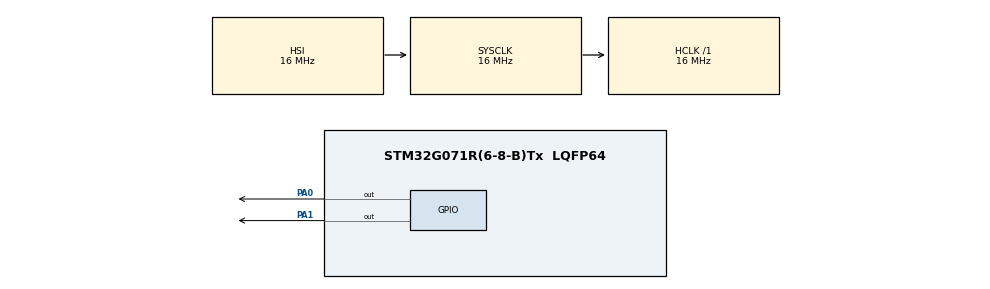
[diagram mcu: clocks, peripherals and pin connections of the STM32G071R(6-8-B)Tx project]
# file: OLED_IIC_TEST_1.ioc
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Mcu.Family=STM32G0
Mcu.Name=STM32G071R(6-8-B)Tx
Mcu.Package=LQFP64
PA0.Signal=GPIO_Output
PA1.Signal=GPIO_Output
ProjectManager.HeapSize=0x200
ProjectManager.StackSize=0x400
ProjectManager.TargetToolchain=MDK-ARM V5.27
RCC.AHBFreq_Value=16000000
RCC.CortexFreq_Value=16000000
RCC.EXTERNAL_CLOCK_VALUE=48000
RCC.HCLKFreq_Value=16000000
RCC.HSE_VALUE=8000000
RCC.HSI_VALUE=16000000
RCC.LSE_VALUE=32768
RCC.SYSCLKFreq_VALUE=16000000
RCC.VCOOutputFreq_Value=128000000
VP_SYS_VS_DBSignals.Mode=DisableDeadBatterySignals
board=custom

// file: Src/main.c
/**************************
		识别图像
		①下载图片
		②打开PS将图片像素改为128*64
		③数据水平，字节垂直
		④字节内像素数据反序
		生成矩阵
		改成二维矩阵（便于理解）
**************************/

/**************************
   GND  电源地
   VCC  接5V或3.3v电源
   D0   PA0（SCL）
   D1   PA1（SDA）
   RES  接高
   DC   接地
   CS   接地
**************************/

#include "main.h"
#define SET		1
#define RESET 0

const unsigned char biaoqinbao[][128] =
{
0X00,0X00,0X00,0X00,0X00,0X00,0X00,0X00,0X00,0X00,0X00,0X00,0X00,0X00,0X00,0X00,
0X00,0X00,0X00,0X00,0X00,0X00,0X00,0X00,0X00,0X00,0X00,0X00,0X00,0X00,0X00,0X00,
0X00,0X00,0X00,0X00,0X00,0X00,0X00,0X00,0X00,0X00,0X00,0X00,0X00,0X00,0X00,0X00,
0X00,0X00,0X00,0X00,0X00,0X00,0X00,0X00,0X00,0X00,0X00,0X00,0X00,0X00,0X00,0X00,
0X00,0X00,0X00,0X00,0X00,0X00,0X00,0X00,0X00,0X00,0X00,0X00,0X00,0X00,0X00,0X00,
0X00,0X00,0X00,0X00,0X00,0X00,0X00,0X00,0X00,0X00,0X00,0X00,0X00,0X00,0X00,0X00,
0X00,0X00,0X00,0X00,0X00,0X00,0X00,0X00,0X00,0X00,0X00,0X00,0X00,0X00,0X00,0X00,
0X00,0X00,0X00,0X00,0X00,0X00,0X00,0X00,0X00,0X00,0X00,0X00,0X00,0X00,0X00,0X00,
0X00,0X00,0X00,0X00,0X00,0X00,0X00,0X00,0X00,0X00,0X00,0X00,0X00,0X00,0X00,0X00,
0X00,0X00,0X00,0X00,0X00,0X00,0X00,0X00,0X00,0X00,0X00,0X00,0X00,0X00,0X00,0X00,
0X00,0X00,0X00,0X00,0X00,0X00,0X00,0X00,0X00,0X00,0X00,0X00,0X00,0X00,0X00,0X00,
0X00,0X00,0X00,0X00,0X00,0X00,0X00,0X80,0X80,0XC0,0XC0,0X60,0X60,0X30,0X30,0X30,
0X30,0X30,0X30,0X30,0X30,0X30,0X30,0X30,0XB0,0X30,0X20,0X60,0X60,0XC0,0XC0,0X80,
0X80,0X00,0X00,0X00,0X00,0X00,0X00,0X00,0X00,0X00,0X00,0X00,0X00,0X00,0X00,0X00,
0X00,0X00,0X00,0X00,0X00,0X00,0X00,0X00,0X00,0X00,0X00,0X00,0X00,0X00,0X00,0X00,
0X00,0X00,0X00,0X00,0X00,0X00,0X00,0X00,0X00,0X00,0X00,0X00,0X00,0X00,0X00,0X00,
0X00,0X00,0X00,0X00,0X00,0X00,0X00,0X00,0X00,0X00,0X00,0X00,0X00,0X00,0X00,0X00,
0X00,0X00,0X00,0X00,0X00,0X00,0X00,0X00,0X00,0X00,0X00,0X00,0X00,0X00,0X00,0X00,
0X00,0X00,0X00,0X00,0X00,0X00,0X00,0X00,0X00,0X00,0X00,0X00,0X00,0X00,0X00,0X00,
0X00,0X80,0XE0,0X78,0X1C,0X0E,0X07,0X03,0X01,0X00,0X80,0X03,0X03,0X01,0X00,0X00,
0X00,0X00,0X00,0X00,0X00,0X80,0X80,0X01,0X03,0X03,0X00,0X00,0X00,0X00,0X00,0X01,
0X03,0X07,0X0E,0X1C,0X70,0XE0,0X00,0X00,0X00,0X00,0X00,0X00,0X00,0X00,0X00,0X00,
0X00,0X00,0X00,0X00,0X00,0X00,0X00,0X00,0X00,0X00,0X00,0X00,0X00,0X00,0X00,0X00,
0X00,0X00,0X00,0X00,0X00,0X00,0X00,0X00,0X00,0X00,0X00,0X00,0X00,0X00,0X00,0X00,
0X00,0X00,0X00,0X00,0X00,0X00,0X00,0X00,0X00,0X00,0X00,0X00,0X00,0X00,0X00,0X00,
0X00,0X00,0X00,0X00,0X00,0X00,0X00,0X00,0X00,0X00,0X00,0X00,0X00,0X00,0X00,0X00,
0X00,0X00,0X00,0X00,0X00,0X00,0X00,0X00,0X00,0X00,0X00,0X00,0X00,0X00,0XF0,0XF8,
0X0E,0X07,0X01,0X08,0X1C,0X1C,0X1C,0X1C,0X1C,0X0F,0X07,0X33,0X30,0X60,0X60,0X60,
0X60,0X60,0X60,0X30,0X33,0X03,0X0F,0X0D,0X0C,0X0C,0X0C,0X0C,0X0C,0X00,0X00,0X00,
0X00,0X00,0X00,0X00,0X00,0X87,0XFF,0X30,0X00,0X00,0X00,0X00,0X00,0X00,0X00,0X00,
0X00,0X00,0X00,0X00,0X00,0X00,0X00,0X00,0X00,0X00,0X00,0X00,0X00,0X00,0X00,0X00,
0X00,0X00,0X00,0X00,0X00,0X00,0X00,0X00,0X00,0X00,0X00,0X00,0X00,0X00,0X00,0X00,
0X00,0X00,0X00,0X00,0X00,0X00,0X00,0X00,0X00,0X00,0X00,0X00,0X00,0X00,0X00,0X00,
0X00,0X00,0X00,0X00,0X00,0X00,0X00,0X00,0X00,0X00,0X00,0X00,0X00,0X00,0X00,0X00,
0X00,0X00,0X00,0X00,0X00,0X00,0X00,0X00,0X00,0X00,0X00,0X00,0X00,0X00,0X07,0X1F,
0X38,0X70,0X60,0XC0,0XC0,0X80,0X80,0X80,0X80,0X80,0X20,0X60,0X40,0XC0,0XC0,0X80,
0XC0,0XC0,0XC0,0X60,0X30,0X00,0X00,0X00,0X00,0X00,0X00,0X00,0X00,0X80,0X80,0X80,
0XC0,0X60,0X70,0X38,0X1C,0X0F,0X03,0X00,0X00,0X00,0X00,0X00,0X00,0X00,0X00,0X00,
0X00,0X00,0X00,0X00,0X00,0X00,0X00,0X00,0X00,0X00,0X00,0X00,0X00,0X00,0X00,0X00,
0X00,0X00,0X00,0X00,0X00,0X00,0X00,0X00,0X00,0X00,0X00,0X00,0X00,0X00,0X00,0X00,
0X00,0X00,0X00,0X00,0X00,0X00,0X00,0X00,0X00,0X00,0X00,0X00,0X00,0X00,0X00,0X00,
0X00,0X00,0X00,0X00,0X00,0X00,0X00,0X00,0X00,0X00,0X00,0X00,0X00,0X00,0X00,0X00,
0X00,0X00,0X00,0X00,0X00,0X00,0X00,0X00,0X00,0X00,0X00,0X00,0X00,0X00,0X00,0X00,
0X80,0XC0,0XE0,0X70,0X1C,0X8F,0XC3,0X61,0X31,0X19,0X08,0X00,0X80,0XC0,0X61,0X39,
0X1D,0X01,0X81,0XE0,0X70,0X38,0X00,0X00,0XF0,0XFE,0X0F,0X03,0X03,0X01,0X01,0X01,
0X00,0X00,0X00,0X00,0X00,0X00,0X00,0X00,0X00,0X00,0X00,0X00,0X00,0X00,0X00,0X00,
0X00,0X00,0X00,0X00,0X00,0X00,0X00,0X00,0X00,0X00,0X00,0X00,0X00,0X00,0X00,0X00,
0X00,0X00,0X00,0X00,0X00,0X00,0X00,0X00,0X00,0X00,0X00,0X00,0X00,0X00,0X00,0X00,
0X00,0X00,0X00,0X00,0X00,0X00,0X00,0X00,0X00,0X00,0X00,0X00,0X00,0X00,0X00,0X00,
0X00,0X00,0X00,0X00,0X00,0X00,0X00,0X00,0X00,0X00,0X00,0X00,0X00,0X00,0X00,0X00,
0X00,0X00,0X00,0X00,0X00,0X00,0X00,0X00,0X00,0X00,0XE0,0XE0,0XF0,0XF8,0XFE,0XE6,
0XC3,0XC7,0XC6,0X83,0X83,0XF9,0XFC,0X86,0X86,0X82,0X82,0X07,0X0D,0X0C,0X9C,0X9E,
0X9F,0X9B,0X99,0XB0,0XF0,0XF0,0XF8,0XFF,0XF7,0XF0,0XE0,0X00,0X00,0X00,0X00,0X00,
0X00,0X00,0X00,0X00,0X00,0X00,0X00,0X00,0X00,0X00,0X00,0X00,0X00,0X00,0X00,0X00,
0X00,0X00,0X00,0X00,0X00,0X00,0X00,0X00,0X00,0X00,0X00,0X00,0X00,0X00,0X00,0X00,
0X00,0X00,0X00,0X00,0X00,0X00,0X00,0X00,0X00,0X00,0X00,0X00,0X00,0X00,0X00,0X00,
0X00,0X00,0X00,0X00,0X00,0X00,0X00,0X00,0X00,0X00,0X00,0X00,0X00,0X00,0X00,0X00,
0X00,0X00,0X00,0X00,0X00,0X00,0X00,0X00,0X00,0X00,0X00,0X00,0X00,0X00,0X00,0X00,
0X00,0X00,0X00,0X00,0X00,0X00,0X00,0X00,0X00,0X00,0X00,0X01,0X01,0X03,0X03,0X03,
0X07,0X07,0X07,0X07,0X07,0X07,0X07,0X07,0X07,0X07,0X07,0X07,0X07,0X07,0X07,0X07,
0X07,0X07,0X07,0X07,0X03,0X03,0X03,0X03,0X01,0X01,0X00,0X00,0X00,0X00,0X00,0X00,
0X00,0X00,0X00,0X00,0X00,0X00,0X00,0X00,0X00,0X00,0X00,0X00,0X00,0X00,0X00,0X00,
0X00,0X00,0X00,0X00,0X00,0X00,0X00,0X00,0X00,0X00,0X00,0X00,0X00,0X00,0X00,0X00,
0X00,0X00,0X00,0X00,0X00,0X00,0X00,0X00,0X00,0X00,0X00,0X00,0X00,0X00,0X00,0X00,
};

unsigned char show[][128]=
{
	{0x00,0x00,0x06,0x0A,0xFE,0x0A,0xC6,0x00,0xE0,0x00,0xF0,0x00,0xF8,0x00,0x00,0x00,
	0x00,0x00,0x00,0xFE,0x7D,0xBB,0xC7,0xEF,0xEF,0xEF,0xEF,0xEF,0xEF,0xEF,0xC7,0xBB,
	0x7D,0xFE,0x00,0x00,0x00,0x00,0x00,0x00,0x00,0x00,0x00,0x00,0x00,0x00,0x00,0x00,
	0x00,0x00,0x00,0x00,0x00,0x00,0x00,0x00,0x00,0x00,0x00,0x00,0x00,0x00,0x00,0x00,
	0x00,0x00,0x00,0x00,0x00,0x00,0x00,0x00,0x00,0x00,0x00,0x00,0x00,0x00,0x00,0x00,
	0x00,0x00,0x00,0x00,0x00,0x00,0x00,0x00,0x00,0x00,0x00,0x00,0x00,0x00,0x00,0x00,
	0x08,0x0C,0xFE,0xFE,0x0C,0x08,0x20,0x60,0xFE,0xFE,0x60,0x20,0x00,0x00,0x00,0x78,
	0x48,0xFE,0x82,0xBA,0xBA,0x82,0xBA,0xBA,0x82,0xBA,0xBA,0x82,0xBA,0xBA,0x82,0xFE},

	{0x00,0x00,0x00,0x00,0x00,0x00,0x00,0x00,0x00,0x00,0x00,0x00,0x00,0x00,0x00,0x00,
	0x00,0x00,0x00,0x00,0x00,0x01,0x01,0x01,0x01,0x01,0x01,0x01,0x01,0x01,0x01,0x01,
	0x01,0x01,0x00,0x00,0x00,0x00,0x00,0x00,0x00,0x00,0x00,0x00,0x00,0x00,0x00,0x00,
	0x00,0x00,0x00,0x00,0x00,0x00,0x00,0x00,0x00,0x00,0x00,0x00,0x00,0x00,0x00,0x00,
	0x00,0x00,0x00,0x00,0x00,0x00,0x00,0x00,0x00,0x00,0x00,0x00,0x00,0x00,0x00,0x00,
	0x00,0x00,0x00,0x00,0x00,0x00,0x00,0x00,0x00,0x00,0x00,0x00,0x00,0x00,0x00,0x00,
	0x00,0x00,0x00,0x00,0x00,0x00,0x00,0x00,0x00,0x00,0x00,0x00,0x00,0x00,0x00,0x00,
	0x00,0x00,0x00,0x00,0x00,0x00,0x00,0x00,0x00,0x00,0x00,0x00,0x00,0x00,0x00,0x00},

	{0x00,0x00,0x00,0x00,0x00,0x00,0x00,0x00,0x00,0x00,0x00,0x00,0x00,0x00,0x00,0x00,
	0x00,0x00,0x00,0x00,0x00,0x00,0x00,0x00,0x00,0x00,0x00,0x00,0x00,0x00,0x00,0x00,
	0xFE,0xFF,0x03,0x03,0x03,0x03,0x03,0x03,0x03,0x03,0x03,0xFF,0xFF,0x00,0x00,0xFE,
	0xFF,0x03,0x03,0x03,0x03,0x03,0x03,0x03,0x03,0x03,0xFF,0xFE,0x00,0x00,0x00,0x00,
	0xC0,0xC0,0xC0,0x00,0x00,0x00,0x00,0xFE,0xFF,0x03,0x03,0x03,0x03,0x03,0x03,0x03,
	0x03,0x03,0xFF,0xFE,0x00,0x00,0xFE,0xFF,0x03,0x03,0x03,0x03,0x03,0x03,0x03,0x03,
	0x03,0xFF,0xFE,0x00,0x00,0x00,0x00,0x00,0x00,0x00,0x00,0x00,0x00,0x00,0x00,0x00,
	0x00,0x00,0x00,0x00,0x00,0x00,0x00,0x00,0x00,0x00,0x00,0x00,0x00,0x00,0x00,0x00},

	{0x00,0x00,0x00,0x00,0x00,0x00,0x00,0x00,0x00,0x00,0x00,0x00,0x00,0x00,0x00,0x00,
	0x00,0x00,0x00,0x00,0x00,0x00,0x00,0x00,0x00,0x00,0x00,0x00,0x00,0x00,0x00,0x00,
	0xFF,0xFF,0x00,0x00,0x00,0x00,0x00,0x00,0x00,0x00,0x00,0xFF,0xFF,0x00,0x00,0xFF,
	0xFF,0x0C,0x0C,0x0C,0x0C,0x0C,0x0C,0x0C,0x0C,0x0C,0xFF,0xFF,0x00,0x00,0x00,0x00,
	0xE1,0xE1,0xE1,0x00,0x00,0x00,0x00,0xFF,0xFF,0x00,0x00,0x00,0x00,0x00,0x00,0x00,
	0x00,0x00,0xFF,0xFF,0x00,0x00,0xFF,0xFF,0x0C,0x0C,0x0C,0x0C,0x0C,0x0C,0x0C,0x0C,
	0x0C,0xFF,0xFF,0x00,0x00,0x00,0x00,0x00,0x00,0x00,0x00,0x00,0x00,0x00,0x00,0x00,
	0x00,0x00,0x00,0x00,0x00,0x00,0x00,0x00,0x00,0x00,0x00,0x00,0x00,0x00,0x00,0x00},

	{0x00,0x00,0x00,0x00,0x00,0x00,0x00,0x00,0x00,0x00,0x00,0x00,0x00,0x00,0x00,0x00,
	0x00,0x00,0x00,0x00,0x00,0x00,0x00,0x00,0x00,0x00,0x00,0x00,0x00,0x00,0x00,0x00,
	0x0F,0x1F,0x18,0x18,0x18,0x18,0x18,0x18,0x18,0x18,0x18,0x1F,0x0F,0x00,0x00,0x0F,
	0x1F,0x18,0x18,0x18,0x18,0x18,0x18,0x18,0x18,0x18,0x1F,0x0F,0x00,0x00,0x00,0x00,
	0x00,0x00,0x00,0x00,0x00,0x00,0x00,0x0F,0x1F,0x18,0x18,0x18,0x18,0x18,0x18,0x18,
	0x18,0x18,0x1F,0x0F,0x00,0x00,0x0F,0x1F,0x18,0x18,0x18,0x18,0x18,0x18,0x18,0x18,
	0x18,0x1F,0x0F,0x00,0x00,0x00,0x00,0x00,0x00,0x00,0x00,0x00,0x00,0x00,0x00,0x00,
	0x00,0x00,0x00,0x00,0x00,0x00,0x00,0x00,0x00,0x00,0x00,0x00,0x00,0x00,0x00,0x00},

	{0x00,0x00,0x00,0x00,0x00,0x00,0x00,0x00,0x00,0x00,0x00,0x00,0x00,0x00,0x00,0x00,
	0x00,0x00,0x00,0x00,0x00,0x00,0x00,0x00,0x00,0x00,0x00,0x00,0x00,0x00,0x00,0x00,
	0x00,0x00,0x00,0x00,0x00,0x00,0x00,0xE2,0x92,0x8A,0x86,0x00,0x00,0x7C,0x82,0x82,
	0x82,0x7C,0x00,0xFE,0x00,0x82,0x92,0xAA,0xC6,0x00,0x00,0xC0,0xC0,0x00,0x7C,0x82,
	0x82,0x82,0x7C,0x00,0x00,0x02,0x02,0x02,0xFE,0x00,0x00,0xC0,0xC0,0x00,0x7C,0x82,
	0x82,0x82,0x7C,0x00,0x00,0xFE,0x00,0x00,0x00,0x00,0x00,0x00,0x00,0x00,0x00,0x00,
	0x00,0x00,0x00,0x00,0x00,0x00,0x00,0x00,0x00,0x00,0x00,0x00,0x00,0x00,0x00,0x00,
	0x00,0x00,0x00,0x00,0x00,0x00,0x00,0x00,0x00,0x00,0x00,0x00,0x00,0x00,0x00,0x00},

	{0x00,0x00,0x00,0x24,0xA4,0x2E,0x24,0xE4,0x24,0x2E,0xA4,0x24,0x00,0x00,0x00,0xF8,
	0x4A,0x4C,0x48,0xF8,0x48,0x4C,0x4A,0xF8,0x00,0x00,0x00,0x00,0x00,0x00,0x00,0x00,
	0x00,0x00,0x00,0x00,0x00,0x00,0x00,0x00,0x00,0x00,0x00,0x00,0x00,0x00,0x00,0x00,
	0x00,0x00,0x00,0x00,0x00,0x00,0x00,0x00,0x00,0x00,0x00,0x00,0x00,0x00,0x00,0x00,
	0x00,0x00,0x00,0x00,0x00,0x00,0x00,0x00,0x00,0x00,0x00,0x00,0x00,0x00,0x00,0x00,
	0x00,0x00,0x00,0x00,0x00,0x00,0x00,0x00,0x00,0x00,0x00,0x00,0x00,0x00,0x00,0x00,
	0x00,0x00,0x00,0x00,0x00,0x00,0x00,0x00,0x00,0x00,0x00,0x00,0x00,0x00,0xC0,0x20,
	0x10,0x10,0x10,0x10,0x20,0xC0,0x00,0x00,0xC0,0x20,0x10,0x10,0x10,0x10,0x20,0xC0},

	{0x00,0x00,0x00,0x12,0x0A,0x07,0x02,0x7F,0x02,0x07,0x0A,0x02,0x00,0x00,0x00,0x0B,
	0x0A,0x0A,0x0A,0x7F,0x0A,0x0A,0x0A,0x0B,0x00,0x00,0x00,0x00,0x00,0x00,0x00,0x00,
	0x00,0x00,0x00,0x00,0x00,0x00,0x00,0x00,0x00,0x00,0x00,0x00,0x00,0x00,0x00,0x00,
	0x00,0x00,0x00,0x00,0x00,0x00,0x00,0x00,0x00,0x00,0x00,0x00,0x00,0x00,0x00,0x00,
	0x00,0x00,0x00,0x00,0x00,0x00,0x00,0x00,0x00,0x00,0x00,0x00,0x00,0x00,0x00,0x00,
	0x00,0x00,0x00,0x00,0x00,0x00,0x00,0x00,0x00,0x00,0x00,0x00,0x00,0x00,0x00,0x00,
	0x00,0x00,0x00,0x00,0x00,0x00,0x00,0x00,0x00,0x00,0x00,0x00,0x00,0x00,0x1F,0x20,
	0x40,0x40,0x40,0x50,0x20,0x5F,0x80,0x00,0x1F,0x20,0x40,0x40,0x40,0x50,0x20,0x5F}
};

void IIC_Start(void);
void IIC_Stop(void);
void Write_IIC_Byte(unsigned char IIC_Byte);
void Write_IIC_Command(unsigned char IIC_Command);
void Initial_M096128x64_ssd1306(void);

void Write_IIC_Data(unsigned char IIC_Data);
void fill_picture(unsigned char fill_Data);
void Picture(int i);

//*************************************************************
const unsigned char L8H16[][8]=
{
  {0x00,0x00,0x00,0x00,0x00,0x00,0x00,0x00},
	{0x00,0x00,0x00,0x00,0x00,0x00,0x00,0x00},//space 0
  {0x00,0x00,0x00,0xF8,0x00,0x00,0x00,0x00},
	{0x00,0x00,0x00,0x33,0x30,0x00,0x00,0x00},//! 1
  {0x00,0x10,0x0C,0x06,0x10,0x0C,0x06,0x00},
	{0x00,0x00,0x00,0x00,0x00,0x00,0x00,0x00},//" 2
  {0x40,0xC0,0x78,0x40,0xC0,0x78,0x40,0x00},
	{0x04,0x3F,0x04,0x04,0x3F,0x04,0x04,0x00},//# 3
  {0x00,0x70,0x88,0xFC,0x08,0x30,0x00,0x00},
	{0x00,0x18,0x20,0xFF,0x21,0x1E,0x00,0x00},//$ 4
  {0xF0,0x08,0xF0,0x00,0xE0,0x18,0x00,0x00},
	{0x00,0x21,0x1C,0x03,0x1E,0x21,0x1E,0x00},//% 5
  {0x00,0xF0,0x08,0x88,0x70,0x00,0x00,0x00},
	{0x1E,0x21,0x23,0x24,0x19,0x27,0x21,0x10},//& 6
  {0x10,0x16,0x0E,0x00,0x00,0x00,0x00,0x00},
	{0x00,0x00,0x00,0x00,0x00,0x00,0x00,0x00},//' 7
  {0x00,0x00,0x00,0xE0,0x18,0x04,0x02,0x00},
	{0x00,0x00,0x00,0x07,0x18,0x20,0x40,0x00},//( 8
  {0x00,0x02,0x04,0x18,0xE0,0x00,0x00,0x00},
	{0x00,0x40,0x20,0x18,0x07,0x00,0x00,0x00},//) 9
  {0x40,0x40,0x80,0xF0,0x80,0x40,0x40,0x00},
	{0x02,0x02,0x01,0x0F,0x01,0x02,0x02,0x00},//* 10
  {0x00,0x00,0x00,0xF0,0x00,0x00,0x00,0x00},
	{0x01,0x01,0x01,0x1F,0x01,0x01,0x01,0x00},//+ 11
  {0x00,0x00,0x00,0x00,0x00,0x00,0x00,0x00},
	{0x80,0xB0,0x70,0x00,0x00,0x00,0x00,0x00},//, 12
  {0x00,0x00,0x00,0x00,0x00,0x00,0x00,0x00},
	{0x00,0x01,0x01,0x01,0x01,0x01,0x01,0x01},//- 13
  {0x00,0x00,0x00,0x00,0x00,0x00,0x00,0x00},
	{0x00,0x30,0x30,0x00,0x00,0x00,0x00,0x00},//. 14
  {0x00,0x00,0x00,0x00,0x80,0x60,0x18,0x04},
	{0x00,0x60,0x18,0x06,0x01,0x00,0x00,0x00},/// 15
  {0x00,0xE0,0x10,0x08,0x08,0x10,0xE0,0x00},
	{0x00,0x0F,0x10,0x20,0x20,0x10,0x0F,0x00},//0 16
  {0x00,0x10,0x10,0xF8,0x00,0x00,0x00,0x00},
	{0x00,0x20,0x20,0x3F,0x20,0x20,0x00,0x00},//1 17
  {0x00,0x70,0x08,0x08,0x08,0x88,0x70,0x00},
	{0x00,0x30,0x28,0x24,0x22,0x21,0x30,0x00},//2 18
  {0x00,0x30,0x08,0x88,0x88,0x48,0x30,0x00},
	{0x00,0x18,0x20,0x20,0x20,0x11,0x0E,0x00},//3 19
  {0x00,0x00,0xC0,0x20,0x10,0xF8,0x00,0x00},
	{0x00,0x07,0x04,0x24,0x24,0x3F,0x24,0x00},//4 20
  {0x00,0xF8,0x08,0x88,0x88,0x08,0x08,0x00},
	{0x00,0x19,0x21,0x20,0x20,0x11,0x0E,0x00},//5 21
  {0x00,0xE0,0x10,0x88,0x88,0x18,0x00,0x00},
	{0x00,0x0F,0x11,0x20,0x20,0x11,0x0E,0x00},//6 22
  {0x00,0x38,0x08,0x08,0xC8,0x38,0x08,0x00},
	{0x00,0x00,0x00,0x3F,0x00,0x00,0x00,0x00},//7 23
  {0x00,0x70,0x88,0x08,0x08,0x88,0x70,0x00},
	{0x00,0x1C,0x22,0x21,0x21,0x22,0x1C,0x00},//8 24
  {0x00,0xE0,0x10,0x08,0x08,0x10,0xE0,0x00},
	{0x00,0x00,0x31,0x22,0x22,0x11,0x0F,0x00},//9 25
  {0x00,0x00,0x00,0xC0,0xC0,0x00,0x00,0x00},
	{0x00,0x00,0x00,0x30,0x30,0x00,0x00,0x00},//: 26
  {0x00,0x00,0x00,0x80,0x00,0x00,0x00,0x00},
	{0x00,0x00,0x80,0x60,0x00,0x00,0x00,0x00},//; 27
  {0x00,0x00,0x80,0x40,0x20,0x10,0x08,0x00},
	{0x00,0x01,0x02,0x04,0x08,0x10,0x20,0x00},//< 28
  {0x40,0x40,0x40,0x40,0x40,0x40,0x40,0x00},
	{0x04,0x04,0x04,0x04,0x04,0x04,0x04,0x00},//= 29
  {0x00,0x08,0x10,0x20,0x40,0x80,0x00,0x00},
	{0x00,0x20,0x10,0x08,0x04,0x02,0x01,0x00},//> 30
  {0x00,0x70,0x48,0x08,0x08,0x08,0xF0,0x00},
	{0x00,0x00,0x00,0x30,0x36,0x01,0x00,0x00},//? 31
  {0xC0,0x30,0xC8,0x28,0xE8,0x10,0xE0,0x00},
	{0x07,0x18,0x27,0x24,0x23,0x14,0x0B,0x00},//@ 32
  {0x00,0x00,0xC0,0x38,0xE0,0x00,0x00,0x00},
	{0x20,0x3C,0x23,0x02,0x02,0x27,0x38,0x20},//A 33
  {0x08,0xF8,0x88,0x88,0x88,0x70,0x00,0x00},
	{0x20,0x3F,0x20,0x20,0x20,0x11,0x0E,0x00},//B 34
  {0xC0,0x30,0x08,0x08,0x08,0x08,0x38,0x00},
	{0x07,0x18,0x20,0x20,0x20,0x10,0x08,0x00},//C 35
  {0x08,0xF8,0x08,0x08,0x08,0x10,0xE0,0x00},
	{0x20,0x3F,0x20,0x20,0x20,0x10,0x0F,0x00},//D 36
  {0x08,0xF8,0x88,0x88,0xE8,0x08,0x10,0x00},
	{0x20,0x3F,0x20,0x20,0x23,0x20,0x18,0x00},//E 37
  {0x08,0xF8,0x88,0x88,0xE8,0x08,0x10,0x00},
	{0x20,0x3F,0x20,0x00,0x03,0x00,0x00,0x00},//F 38
  {0xC0,0x30,0x08,0x08,0x08,0x38,0x00,0x00},
	{0x07,0x18,0x20,0x20,0x22,0x1E,0x02,0x00},//G 39
  {0x08,0xF8,0x08,0x00,0x00,0x08,0xF8,0x08},
	{0x20,0x3F,0x21,0x01,0x01,0x21,0x3F,0x20},//H 40
  {0x00,0x08,0x08,0xF8,0x08,0x08,0x00,0x00},
	{0x00,0x20,0x20,0x3F,0x20,0x20,0x00,0x00},//I 41
  {0x00,0x00,0x08,0x08,0xF8,0x08,0x08,0x00},
	{0xC0,0x80,0x80,0x80,0x7F,0x00,0x00,0x00},//J 42
  {0x08,0xF8,0x88,0xC0,0x28,0x18,0x08,0x00},
	{0x20,0x3F,0x20,0x01,0x26,0x38,0x20,0x00},//K 43
  {0x08,0xF8,0x08,0x00,0x00,0x00,0x00,0x00},
	{0x20,0x3F,0x20,0x20,0x20,0x20,0x30,0x00},//L 44
  {0x08,0xF8,0xF8,0x00,0xF8,0xF8,0x08,0x00},
	{0x20,0x3F,0x00,0x3F,0x00,0x3F,0x20,0x00},//M 45
  {0x08,0xF8,0x30,0xC0,0x00,0x08,0xF8,0x08},
	{0x20,0x3F,0x20,0x00,0x07,0x18,0x3F,0x00},//N 46
  {0xE0,0x10,0x08,0x08,0x08,0x10,0xE0,0x00},
	{0x0F,0x10,0x20,0x20,0x20,0x10,0x0F,0x00},//O 47
  {0x08,0xF8,0x08,0x08,0x08,0x08,0xF0,0x00},
	{0x20,0x3F,0x21,0x01,0x01,0x01,0x00,0x00},//P 48
  {0xE0,0x10,0x08,0x08,0x08,0x10,0xE0,0x00},
	{0x0F,0x18,0x24,0x24,0x38,0x50,0x4F,0x00},//Q 49
  {0x08,0xF8,0x88,0x88,0x88,0x88,0x70,0x00},
	{0x20,0x3F,0x20,0x00,0x03,0x0C,0x30,0x20},//R 50
  {0x00,0x70,0x88,0x08,0x08,0x08,0x38,0x00},
	{0x00,0x38,0x20,0x21,0x21,0x22,0x1C,0x00},//S 51
  {0x18,0x08,0x08,0xF8,0x08,0x08,0x18,0x00},
	{0x00,0x00,0x20,0x3F,0x20,0x00,0x00,0x00},//T 52
  {0x08,0xF8,0x08,0x00,0x00,0x08,0xF8,0x08},
	{0x00,0x1F,0x20,0x20,0x20,0x20,0x1F,0x00},//U 53
  {0x08,0x78,0x88,0x00,0x00,0xC8,0x38,0x08},
	{0x00,0x00,0x07,0x38,0x0E,0x01,0x00,0x00},//V 54
  {0xF8,0x08,0x00,0xF8,0x00,0x08,0xF8,0x00},
	{0x03,0x3C,0x07,0x00,0x07,0x3C,0x03,0x00},//W 55
  {0x08,0x18,0x68,0x80,0x80,0x68,0x18,0x08},
	{0x20,0x30,0x2C,0x03,0x03,0x2C,0x30,0x20},//X 56
  {0x08,0x38,0xC8,0x00,0xC8,0x38,0x08,0x00},
	{0x00,0x00,0x20,0x3F,0x20,0x00,0x00,0x00},//Y 57
  {0x10,0x08,0x08,0x08,0xC8,0x38,0x08,0x00},
	{0x20,0x38,0x26,0x21,0x20,0x20,0x18,0x00},//Z 58
  {0x00,0x00,0x00,0xFE,0x02,0x02,0x02,0x00},
	{0x00,0x00,0x00,0x7F,0x40,0x40,0x40,0x00},//[ 59
  {0x00,0x0C,0x30,0xC0,0x00,0x00,0x00,0x00},
	{0x00,0x00,0x00,0x01,0x06,0x38,0xC0,0x00},//\ 60
  {0x00,0x02,0x02,0x02,0xFE,0x00,0x00,0x00},
	{0x00,0x40,0x40,0x40,0x7F,0x00,0x00,0x00},//] 61
  {0x00,0x00,0x04,0x02,0x02,0x02,0x04,0x00},
	{0x00,0x00,0x00,0x00,0x00,0x00,0x00,0x00},//^ 62
  {0x00,0x00,0x00,0x00,0x00,0x00,0x00,0x00},
	{0x80,0x80,0x80,0x80,0x80,0x80,0x80,0x80},//_ 63
  {0x00,0x02,0x02,0x04,0x00,0x00,0x00,0x00},
	{0x00,0x00,0x00,0x00,0x00,0x00,0x00,0x00},//` 64
  {0x00,0x00,0x80,0x80,0x80,0x80,0x00,0x00},
	{0x00,0x19,0x24,0x22,0x22,0x22,0x3F,0x20},//a 65
  {0x08,0xF8,0x00,0x80,0x80,0x00,0x00,0x00},
	{0x00,0x3F,0x11,0x20,0x20,0x11,0x0E,0x00},//b 66
  {0x00,0x00,0x00,0x80,0x80,0x80,0x00,0x00},
	{0x00,0x0E,0x11,0x20,0x20,0x20,0x11,0x00},//c 67
  {0x00,0x00,0x00,0x80,0x80,0x88,0xF8,0x00},
	{0x00,0x0E,0x11,0x20,0x20,0x10,0x3F,0x20},//d 68
  {0x00,0x00,0x80,0x80,0x80,0x80,0x00,0x00},
	{0x00,0x1F,0x22,0x22,0x22,0x22,0x13,0x00},//e 69
  {0x00,0x80,0x80,0xF0,0x88,0x88,0x88,0x18},
	{0x00,0x20,0x20,0x3F,0x20,0x20,0x00,0x00},//f 70
  {0x00,0x00,0x80,0x80,0x80,0x80,0x80,0x00},
	{0x00,0x6B,0x94,0x94,0x94,0x93,0x60,0x00},//g 71
  {0x08,0xF8,0x00,0x80,0x80,0x80,0x00,0x00},
	{0x20,0x3F,0x21,0x00,0x00,0x20,0x3F,0x20},//h 72
  {0x00,0x80,0x98,0x98,0x00,0x00,0x00,0x00},
	{0x00,0x20,0x20,0x3F,0x20,0x20,0x00,0x00},//i 73
  {0x00,0x00,0x00,0x80,0x98,0x98,0x00,0x00},
	{0x00,0xC0,0x80,0x80,0x80,0x7F,0x00,0x00},//j 74
  {0x08,0xF8,0x00,0x00,0x80,0x80,0x80,0x00},
	{0x20,0x3F,0x24,0x02,0x2D,0x30,0x20,0x00},//k 75
  {0x00,0x08,0x08,0xF8,0x00,0x00,0x00,0x00},
	{0x00,0x20,0x20,0x3F,0x20,0x20,0x00,0x00},//l 76
  {0x80,0x80,0x80,0x80,0x80,0x80,0x80,0x00},
	{0x20,0x3F,0x20,0x00,0x3F,0x20,0x00,0x3F},//m 77
  {0x80,0x80,0x00,0x80,0x80,0x80,0x00,0x00},
	{0x20,0x3F,0x21,0x00,0x00,0x20,0x3F,0x20},//n 78
  {0x00,0x00,0x80,0x80,0x80,0x80,0x00,0x00},
	{0x00,0x1F,0x20,0x20,0x20,0x20,0x1F,0x00},//o 79
  {0x80,0x80,0x00,0x80,0x80,0x00,0x00,0x00},
	{0x80,0xFF,0xA1,0x20,0x20,0x11,0x0E,0x00},//p 80
  {0x00,0x00,0x00,0x80,0x80,0x80,0x80,0x00},
	{0x00,0x0E,0x11,0x20,0x20,0xA0,0xFF,0x80},//q 81
  {0x80,0x80,0x80,0x00,0x80,0x80,0x80,0x00},
	{0x20,0x20,0x3F,0x21,0x20,0x00,0x01,0x00},//r 82
  {0x00,0x00,0x80,0x80,0x80,0x80,0x80,0x00},
	{0x00,0x33,0x24,0x24,0x24,0x24,0x19,0x00},//s 83
  {0x00,0x80,0x80,0xE0,0x80,0x80,0x00,0x00},
	{0x00,0x00,0x00,0x1F,0x20,0x20,0x00,0x00},//t 84
  {0x80,0x80,0x00,0x00,0x00,0x80,0x80,0x00},
	{0x00,0x1F,0x20,0x20,0x20,0x10,0x3F,0x20},//u 85
  {0x80,0x80,0x80,0x00,0x00,0x80,0x80,0x80},
	{0x00,0x01,0x0E,0x30,0x08,0x06,0x01,0x00},//v 86
  {0x80,0x80,0x00,0x80,0x00,0x80,0x80,0x80},
	{0x0F,0x30,0x0C,0x03,0x0C,0x30,0x0F,0x00},//w 87
  {0x00,0x80,0x80,0x00,0x80,0x80,0x80,0x00},
	{0x00,0x20,0x31,0x2E,0x0E,0x31,0x20,0x00},//x 88
  {0x80,0x80,0x80,0x00,0x00,0x80,0x80,0x80},
	{0x80,0x81,0x8E,0x70,0x18,0x06,0x01,0x00},//y 89
  {0x00,0x80,0x80,0x80,0x80,0x80,0x80,0x00},
	{0x00,0x21,0x30,0x2C,0x22,0x21,0x30,0x00},//z 90
  {0x00,0x00,0x00,0x00,0x80,0x7C,0x02,0x02},
	{0x00,0x00,0x00,0x00,0x00,0x3F,0x40,0x40},//{ 91
  {0x00,0x00,0x00,0x00,0xFF,0x00,0x00,0x00},
	{0x00,0x00,0x00,0x00,0xFF,0x00,0x00,0x00},//| 92
  {0x00,0x02,0x02,0x7C,0x80,0x00,0x00,0x00},
	{0x00,0x40,0x40,0x3F,0x00,0x00,0x00,0x00},//} 93
  {0x00,0x06,0x01,0x01,0x02,0x02,0x04,0x04},
	{0x00,0x00,0x00,0x00,0x00,0x00,0x00,0x00},//~ 94
};

void OLED_ShowChar(unsigned char x,unsigned char y,unsigned char chr);
void OLED_ShowString(unsigned char  x,unsigned char  y, unsigned char  *p);
void SystemClock_Config(void);
static void MX_GPIO_Init(void);

int main(void)
{
  HAL_Init();
  SystemClock_Config();
  MX_GPIO_Init();

	Initial_M096128x64_ssd1306();
	HAL_Delay(5);
  while (1)
  {
/*
		fill_picture(0xff);//全屏显示
		HAL_Delay(3000);
		fill_picture(0xf0);//半屏熄灭；出现一条一条的亮线
		HAL_Delay(3000);
*/

		fill_picture(0x00);
		OLED_ShowString(0,0,"ABCDEFGHIJKLMNOPQ");
		HAL_Delay(3000);

		Picture(1);//显示一张图片
		HAL_Delay(3000);

		Picture(2);//显示二张图片
		HAL_Delay(3000);
  }
}

void SystemClock_Config(void)
{
  RCC_OscInitTypeDef RCC_OscInitStruct = {0};
  RCC_ClkInitTypeDef RCC_ClkInitStruct = {0};
  HAL_PWREx_ControlVoltageScaling(PWR_REGULATOR_VOLTAGE_SCALE1);
  RCC_OscInitStruct.OscillatorType = RCC_OSCILLATORTYPE_HSI;
  RCC_OscInitStruct.HSIState = RCC_HSI_ON;
  RCC_OscInitStruct.HSIDiv = RCC_HSI_DIV1;
  RCC_OscInitStruct.HSICalibrationValue = RCC_HSICALIBRATION_DEFAULT;
  RCC_OscInitStruct.PLL.PLLState = RCC_PLL_NONE;
  if (HAL_RCC_OscConfig(&RCC_OscInitStruct) != HAL_OK)
  {
    Error_Handler();
  }
  RCC_ClkInitStruct.ClockType = RCC_CLOCKTYPE_HCLK|RCC_CLOCKTYPE_SYSCLK
                              |RCC_CLOCKTYPE_PCLK1;
  RCC_ClkInitStruct.SYSCLKSource = RCC_SYSCLKSOURCE_HSI;
  RCC_ClkInitStruct.AHBCLKDivider = RCC_SYSCLK_DIV1;
  RCC_ClkInitStruct.APB1CLKDivider = RCC_HCLK_DIV1;

  if (HAL_RCC_ClockConfig(&RCC_ClkInitStruct, FLASH_LATENCY_0) != HAL_OK)
  {
    Error_Handler();
  }
}

static void MX_GPIO_Init(void)
{
  GPIO_InitTypeDef GPIO_InitStruct = {0};
  __HAL_RCC_GPIOA_CLK_ENABLE();
  HAL_GPIO_WritePin(GPIOA, GPIO_PIN_0|GPIO_PIN_1, GPIO_PIN_RESET);
  GPIO_InitStruct.Pin = GPIO_PIN_0|GPIO_PIN_1;
  GPIO_InitStruct.Mode = GPIO_MODE_OUTPUT_PP;
  GPIO_InitStruct.Pull = GPIO_NOPULL;
  GPIO_InitStruct.Speed = GPIO_SPEED_FREQ_LOW;
  HAL_GPIO_Init(GPIOA, &GPIO_InitStruct);

}

/* USER CODE BEGIN 4 */

void IIC_Start()
{
   HAL_GPIO_WritePin(GPIOA,GPIO_PIN_0,SET);//SCL = high;
   HAL_GPIO_WritePin(GPIOA,GPIO_PIN_1,SET);//SDA = high;
   HAL_GPIO_WritePin(GPIOA,GPIO_PIN_1,RESET);//SDA = low;
   HAL_GPIO_WritePin(GPIOA,GPIO_PIN_0,RESET);//SCL = low;
}

void IIC_Stop()
{
   HAL_GPIO_WritePin(GPIOA,GPIO_PIN_0,RESET);//SCL = low;
   HAL_GPIO_WritePin(GPIOA,GPIO_PIN_1,RESET);//SDA = low;
   HAL_GPIO_WritePin(GPIOA,GPIO_PIN_0,SET);//SCL = high;
   HAL_GPIO_WritePin(GPIOA,GPIO_PIN_1,SET);//SDA = high;
}

void Write_IIC_Byte(unsigned char IIC_Byte)
{
	for(unsigned char i=0;i<8;i++)
	{
		if(IIC_Byte & 0x80)
			HAL_GPIO_WritePin(GPIOA,GPIO_PIN_1,SET);//SDA=high;
		else
			HAL_GPIO_WritePin(GPIOA,GPIO_PIN_1,RESET);//SDA=low;
		HAL_GPIO_WritePin(GPIOA,GPIO_PIN_0,SET);//SCL=high;
		HAL_GPIO_WritePin(GPIOA,GPIO_PIN_0,RESET);//SCL=low;
		IIC_Byte<<=1;
	}
	HAL_GPIO_WritePin(GPIOA,GPIO_PIN_1,SET);//SDA=1;
	HAL_GPIO_WritePin(GPIOA,GPIO_PIN_0,SET);//SCL=1;
	HAL_GPIO_WritePin(GPIOA,GPIO_PIN_0,RESET);//SCL=0;
}

void Write_IIC_Command(unsigned char IIC_Command)
{
   IIC_Start();
   Write_IIC_Byte(0x78);      //Slave address,SA0=0
   Write_IIC_Byte(0x00);			//write command
   Write_IIC_Byte(IIC_Command);
   IIC_Stop();
}

void Initial_M096128x64_ssd1306()
{
	Write_IIC_Command(0xAE);   //display off
	Write_IIC_Command(0x20);	//Set Memory Addressing Mode
	Write_IIC_Command(0x10);	//00,Horizontal Addressing Mode;01,Vertical Addressing Mode;10,Page Addressing Mode (RESET);11,Invalid
	Write_IIC_Command(0xb0);	//Set Page Start Address for Page Addressing Mode,0-7
	Write_IIC_Command(0xc8);	//Set COM Output Scan Direction
	Write_IIC_Command(0x00);//---set low column address
	Write_IIC_Command(0x10);//---set high column address
	Write_IIC_Command(0x40);//--set start line address
	Write_IIC_Command(0x81);//--set contrast control register
	Write_IIC_Command(0xdf);
	Write_IIC_Command(0xa1);//--set segment re-map 0 to 127
	Write_IIC_Command(0xa6);//--set normal display
	Write_IIC_Command(0xa8);//--set multiplex ratio(1 to 64)
	Write_IIC_Command(0x3F);//
	Write_IIC_Command(0xa4);//0xa4,Output follows RAM content;0xa5,Output ignores RAM content
	Write_IIC_Command(0xd3);//-set display offset
	Write_IIC_Command(0x00);//-not offset
	Write_IIC_Command(0xd5);//--set display clock divide ratio/oscillator frequency
	Write_IIC_Command(0xf0);//--set divide ratio
	Write_IIC_Command(0xd9);//--set pre-charge period
	Write_IIC_Command(0x22); //
	Write_IIC_Command(0xda);//--set com pins hardware configuration
	Write_IIC_Command(0x12);
	Write_IIC_Command(0xdb);//--set vcomh
	Write_IIC_Command(0x20);//0x20,0.77xVcc
	Write_IIC_Command(0x8d);//--set DC-DC enable
	Write_IIC_Command(0x14);//
	Write_IIC_Command(0xaf);//--turn on oled panel
}

//****************************************************************

void Picture(int i)
{
  for(unsigned char y=0;y<8;y++)
    {
      Write_IIC_Command(0xb0+y);
      Write_IIC_Command(0x0);
      Write_IIC_Command(0x10);
      for(unsigned char x=0;x<128;x++)
			{
				if(i==1)
					Write_IIC_Data(show[y][x]);
				else if(i==2)
					Write_IIC_Data(biaoqinbao[y][x]);
				else ;
			}
    }
}

void Write_IIC_Data(unsigned char IIC_Data)
{
   IIC_Start();
   Write_IIC_Byte(0x78);			//D/C#=0; R/W#=0
   Write_IIC_Byte(0x40);			//write data
   Write_IIC_Byte(IIC_Data);
   IIC_Stop();
}

void fill_picture(unsigned char fill_Data)
{
	for(unsigned char m=0;m<8;m++)
	{
		Write_IIC_Command(0xb0+m);	//page0-page1
		Write_IIC_Command(0x00);		//low column start address
		Write_IIC_Command(0x10);		//high column start address
		for(unsigned char n=0;n<128;n++)
			{
				Write_IIC_Data(fill_Data);
			}
	}
}
//***************************************************************
void OLED_ShowChar(unsigned char x,unsigned char y,unsigned char chr)
{
	unsigned char nomber=0;
	nomber=chr-' ';//得到偏移后的值即ASC码偏移量  设置空格为0号字符
	if(x>127)	//如果超出这一行自动跳转到下一行（+2）
	{
		x=0;
		y=y+2;
	}
   Write_IIC_Command(0xb0+y);
   Write_IIC_Command(0x00+x%16); //低四位横坐标
   Write_IIC_Command(0x10+x/16);//高四位横坐标
	for(int i=0;i<8;i++)
		Write_IIC_Data(L8H16[nomber*2][i]);

   Write_IIC_Command(0xb0+y+1);
   Write_IIC_Command(0x00+x%16);
   Write_IIC_Command(0x10+x/16);
	for(int i=0;i<8;i++)
		Write_IIC_Data(L8H16[nomber*2+1][i]);

}

void OLED_ShowString(unsigned char x,unsigned char y,unsigned char *chr)
{
	unsigned char i=0;
	while (chr[i]!='\0')	//不是字符串的结束则一直循环
	{
		OLED_ShowChar(x,y,chr[i]);	//在x，y处显示字符
		x+=8;												//x=x+8 列地址加8准备显示下一字符
		if(x>120)										//位置不够显示当前字符，去下一行显示
		{
			x=0;
			y+=2;
		}
		i++;	//扫描下一字符
	}
}

/* USER CODE END 4 */

void Error_Handler(void)
{
  __disable_irq();
  while (1)
  {
  }
  /* USER CODE END Error_Handler_Debug */
}

/************************ (C) COPYRIGHT STMicroelectronics *****END OF FILE****/
